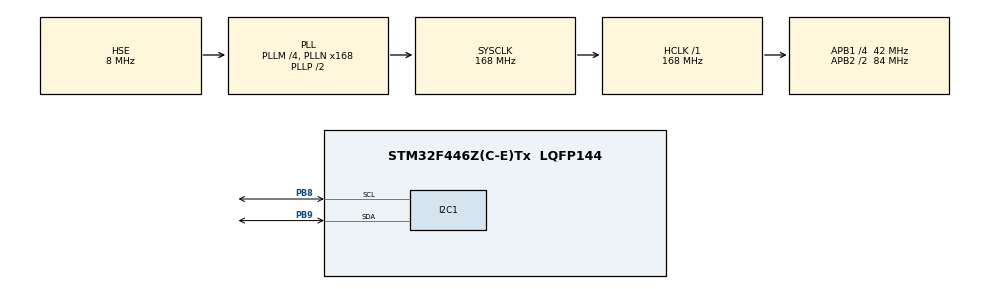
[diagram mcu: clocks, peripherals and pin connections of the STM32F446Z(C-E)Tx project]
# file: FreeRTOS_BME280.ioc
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FREERTOS.Tasks01=defaultTask,24,128,StartDefaultTask,Default,NULL,Dynamic,NULL,NULL
FREERTOS.configUSE_NEWLIB_REENTRANT=1
Mcu.Family=STM32F4
Mcu.Name=STM32F446Z(C-E)Tx
Mcu.Package=LQFP144
NVIC.PriorityGroup=NVIC_PRIORITYGROUP_4
NVIC.TIM7_IRQn=true\:15\:0\:false\:false\:true\:false\:false\:true\:true
NVIC.TimeBase=TIM7_IRQn
NVIC.TimeBaseIP=TIM7
PB8.Mode=I2C
PB8.Signal=I2C1_SCL
PB9.Mode=I2C
PB9.Signal=I2C1_SDA
PH0-OSC_IN.Mode=HSE-External-Oscillator
PH0-OSC_IN.Signal=RCC_OSC_IN
PH1-OSC_OUT.Mode=HSE-External-Oscillator
PH1-OSC_OUT.Signal=RCC_OSC_OUT
ProjectManager.HeapSize=0x200
ProjectManager.StackSize=0x400
ProjectManager.TargetToolchain=STM32CubeIDE
RCC.AHBFreq_Value=168000000
RCC.APB1CLKDivider=RCC_HCLK_DIV4
RCC.APB1Freq_Value=42000000
RCC.APB1TimFreq_Value=84000000
RCC.APB2CLKDivider=RCC_HCLK_DIV2
RCC.APB2Freq_Value=84000000
RCC.APB2TimFreq_Value=168000000
RCC.CortexFreq_Value=168000000
RCC.HCLKFreq_Value=168000000
RCC.HSE_VALUE=8000000
RCC.PLLM=4
RCC.PLLN=168
RCC.PLLSourceVirtual=RCC_PLLSOURCE_HSE
RCC.SYSCLKFreq_VALUE=168000000
RCC.SYSCLKSource=RCC_SYSCLKSOURCE_PLLCLK
RCC.USBFreq_Value=168000000
RCC.VCOOutputFreq_Value=336000000
VP_FREERTOS_VS_CMSIS_V2.Mode=CMSIS_V2
VP_SYS_VS_tim7.Mode=TIM7
board=custom

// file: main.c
/* USER CODE BEGIN Header */
/**
  ******************************************************************************
  * @file           : main.c
  * @brief          : Main program body
  ******************************************************************************
  * @attention
  *
  * Copyright (c) 2025 STMicroelectronics.
  * All rights reserved.
  *
  * This software is licensed under terms that can be found in the LICENSE file
  * in the root directory of this software component.
  * If no LICENSE file comes with this software, it is provided AS-IS.
  *
  ******************************************************************************
  */
/* USER CODE END Header */
#include "main.h"
#include "cmsis_os.h"

/* USER CODE BEGIN Includes */
#include "FreeRTOS.h"
#include "queue.h"
#include "task.h"
#include "stdio.h"
/* USER CODE END Includes */

/* USER CODE BEGIN PD */
#define BME280_I2C_ADDRESS  0x76 << 1  // BME280 I2C address (SDO = GND => 0x76, SDO = VCC => 0x77)
// BME280 Register Adresses
#define BME280_REG_ID        0xD0
#define BME280_REG_RESET     0xE0
#define BME280_REG_STATUS    0xF3
#define BME280_REG_CTRL_MEAS 0xF4
#define BME280_REG_CONFIG    0xF5
#define BME280_REG_TEMP_MSB  0xFA
#define BME280_REG_PRESS_MSB 0xF7

#define BME280_CALIB_DATA_START  0x88
#define BME280_CALIB_DATA_END    0xA1

/* USER CODE END PD */

I2C_HandleTypeDef hi2c1;

/* Definitions for defaultTask */
/*osThreadId_t defaultTaskHandle;
const osThreadAttr_t defaultTask_attributes = {
  .name = "defaultTask",
  .stack_size = 128 * 4,
  .priority = (osPriority_t) osPriorityNormal,
};*/

/* USER CODE BEGIN PV */
uint16_t dig_T1;
int16_t dig_T2, dig_T3;
QueueHandle_t xQueue;
float temp;

uint8_t sender;
uint8_t receiver;
uint8_t senderCheck;
uint8_t receiverCheck;
uint8_t messageWaiting;
uint8_t isQueueCreated;
/* USER CODE END PV */

void SystemClock_Config(void);
static void MX_GPIO_Init(void);
static void MX_I2C1_Init(void);
void StartDefaultTask(void *argument);

/* USER CODE BEGIN 0 */

void BME280_Read_Calibration() {
    uint8_t calib_data[26];
    HAL_I2C_Mem_Read(&hi2c1, BME280_I2C_ADDRESS, BME280_CALIB_DATA_START, 1, calib_data, 26, HAL_MAX_DELAY);

    dig_T1 = (calib_data[1] << 8) | calib_data[0];
    dig_T2 = (calib_data[3] << 8) | calib_data[2];
    dig_T3 = (calib_data[5] << 8) | calib_data[4];
}

void vBME280_Compensate_Temperature(void *pvParameters){
    int32_t var1, var2, T;
    uint8_t data[8];

    BaseType_t xStatus;

    for(;;){

        HAL_I2C_Mem_Read(&hi2c1, BME280_I2C_ADDRESS, BME280_REG_PRESS_MSB, 1, data, 8, HAL_MAX_DELAY);

        int32_t adc_T = ((uint32_t)data[3] << 12) | ((uint32_t)data[4] << 4) | ((uint32_t)data[5] >> 4);

        var1 = ((((adc_T >> 3) - ((int32_t)dig_T1 << 1))) * ((int32_t)dig_T2)) >> 11;
        var2 = (((((adc_T >> 4) - ((int32_t)dig_T1)) * ((adc_T >> 4) - ((int32_t)dig_T1))) >> 12) * ((int32_t)dig_T3)) >> 14;
        T = (((var1 + var2) * 5) + 128) >> 8;

    	xStatus = xQueueSendToBack(xQueue, &T, 0);
    	sender = 1;
    	receiver = 0;
    	if(xStatus != pdPASS){
    		senderCheck = 0;
    	}else{
    		senderCheck = 1;
    	}

    }
}

void vBME280_Read_Data(void *pvParameters) {

    int32_t lReceivedValue;
    BaseType_t xStatus;

    const TickType_t xTicksToWait = pdMS_TO_TICKS( 100 );

    for (;;){

        if(uxQueueMessagesWaiting(xQueue) != 0){
        	messageWaiting = 1;
        }

        xStatus = xQueueReceive(xQueue, &lReceivedValue, xTicksToWait);
    	sender = 0;
    	receiver = 1;

        if(xStatus == pdPASS){
        	receiverCheck = 1;
        	temp = (float)lReceivedValue / 100;
        }
        else{
        	receiverCheck = 0;
        }
    }
}

void BME280_Init() {
    uint8_t id;
    HAL_I2C_Mem_Read(&hi2c1, BME280_I2C_ADDRESS, BME280_REG_ID, 1, &id, 1, HAL_MAX_DELAY);
    if (id != 0x60) {
        printf("BME280 Could not find!\n");
    }

    uint8_t reset_cmd = 0xB6;
    HAL_I2C_Mem_Write(&hi2c1, BME280_I2C_ADDRESS, BME280_REG_RESET, 1, &reset_cmd, 1, HAL_MAX_DELAY);
    HAL_Delay(10);

    uint8_t filter = 0xA4;
    HAL_I2C_Mem_Write(&hi2c1, BME280_I2C_ADDRESS, BME280_REG_CONFIG, 1, &filter, 1, HAL_MAX_DELAY);

    BME280_Read_Calibration();

    uint8_t ctrl_meas = 0x67;
    HAL_I2C_Mem_Write(&hi2c1, BME280_I2C_ADDRESS, BME280_REG_CTRL_MEAS, 1, &ctrl_meas, 1, HAL_MAX_DELAY);
}

/* USER CODE END 0 */

int main(void)
{

  /* MCU Configuration--------------------------------------------------------*/

  /* Reset of all peripherals, Initializes the Flash interface and the Systick. */
  HAL_Init();

  /* Configure the system clock */
  SystemClock_Config();

  /* Initialize all configured peripherals */
  MX_GPIO_Init();
  MX_I2C1_Init();
  /* USER CODE BEGIN 2 */
  BME280_Init();

  xQueue = xQueueCreate( 3, sizeof( int32_t ) );

  if( xQueue != NULL ){
	  isQueueCreated = 1;
	  xTaskCreate(vBME280_Compensate_Temperature, "Sender1", 1000, NULL, 1, NULL);
	  xTaskCreate(vBME280_Compensate_Temperature, "Sender2", 1000, NULL, 1, NULL);

	  xTaskCreate(vBME280_Read_Data, "Receiver", 1000, NULL, 2, NULL);

	  vTaskStartScheduler();
  }else{
	  isQueueCreated = 0;
  }

  for(;;);

  /* USER CODE END 2 */

  /* Init scheduler */
  //osKernelInitialize();

  /* Create the thread(s) */
  /* creation of defaultTask */
  //defaultTaskHandle = osThreadNew(StartDefaultTask, NULL, &defaultTask_attributes);

  /* Start scheduler */
  //osKernelStart();

  /* We should never get here as control is now taken by the scheduler */

  /* Infinite loop */
  while (1)
  {

  }
}

void SystemClock_Config(void)
{
  RCC_OscInitTypeDef RCC_OscInitStruct = {0};
  RCC_ClkInitTypeDef RCC_ClkInitStruct = {0};

  /** Configure the main internal regulator output voltage
  */
  __HAL_RCC_PWR_CLK_ENABLE();
  __HAL_PWR_VOLTAGESCALING_CONFIG(PWR_REGULATOR_VOLTAGE_SCALE1);

  /** Initializes the RCC Oscillators according to the specified parameters
  * in the RCC_OscInitTypeDef structure.
  */
  RCC_OscInitStruct.OscillatorType = RCC_OSCILLATORTYPE_HSE;
  RCC_OscInitStruct.HSEState = RCC_HSE_ON;
  RCC_OscInitStruct.PLL.PLLState = RCC_PLL_ON;
  RCC_OscInitStruct.PLL.PLLSource = RCC_PLLSOURCE_HSE;
  RCC_OscInitStruct.PLL.PLLM = 4;
  RCC_OscInitStruct.PLL.PLLN = 168;
  RCC_OscInitStruct.PLL.PLLP = RCC_PLLP_DIV2;
  RCC_OscInitStruct.PLL.PLLQ = 2;
  RCC_OscInitStruct.PLL.PLLR = 2;
  if (HAL_RCC_OscConfig(&RCC_OscInitStruct) != HAL_OK)
  {
    Error_Handler();
  }

  /** Initializes the CPU, AHB and APB buses clocks
  */
  RCC_ClkInitStruct.ClockType = RCC_CLOCKTYPE_HCLK|RCC_CLOCKTYPE_SYSCLK
                              |RCC_CLOCKTYPE_PCLK1|RCC_CLOCKTYPE_PCLK2;
  RCC_ClkInitStruct.SYSCLKSource = RCC_SYSCLKSOURCE_PLLCLK;
  RCC_ClkInitStruct.AHBCLKDivider = RCC_SYSCLK_DIV1;
  RCC_ClkInitStruct.APB1CLKDivider = RCC_HCLK_DIV4;
  RCC_ClkInitStruct.APB2CLKDivider = RCC_HCLK_DIV2;

  if (HAL_RCC_ClockConfig(&RCC_ClkInitStruct, FLASH_LATENCY_5) != HAL_OK)
  {
    Error_Handler();
  }
}

static void MX_I2C1_Init(void)
{

  hi2c1.Instance = I2C1;
  hi2c1.Init.ClockSpeed = 100000;
  hi2c1.Init.DutyCycle = I2C_DUTYCYCLE_2;
  hi2c1.Init.OwnAddress1 = 0;
  hi2c1.Init.AddressingMode = I2C_ADDRESSINGMODE_7BIT;
  hi2c1.Init.DualAddressMode = I2C_DUALADDRESS_DISABLE;
  hi2c1.Init.OwnAddress2 = 0;
  hi2c1.Init.GeneralCallMode = I2C_GENERALCALL_DISABLE;
  hi2c1.Init.NoStretchMode = I2C_NOSTRETCH_DISABLE;
  if (HAL_I2C_Init(&hi2c1) != HAL_OK)
  {
    Error_Handler();
  }

}

static void MX_GPIO_Init(void)
{

  /* GPIO Ports Clock Enable */
  __HAL_RCC_GPIOH_CLK_ENABLE();
  __HAL_RCC_GPIOB_CLK_ENABLE();

}

void StartDefaultTask(void *argument)
{
  for(;;)
  {
    osDelay(1);
  }
}

void HAL_TIM_PeriodElapsedCallback(TIM_HandleTypeDef *htim)
{
  if (htim->Instance == TIM7)
  {
    HAL_IncTick();
  }
}

void Error_Handler(void)
{
  __disable_irq();
  while (1)
  {
  }
}
